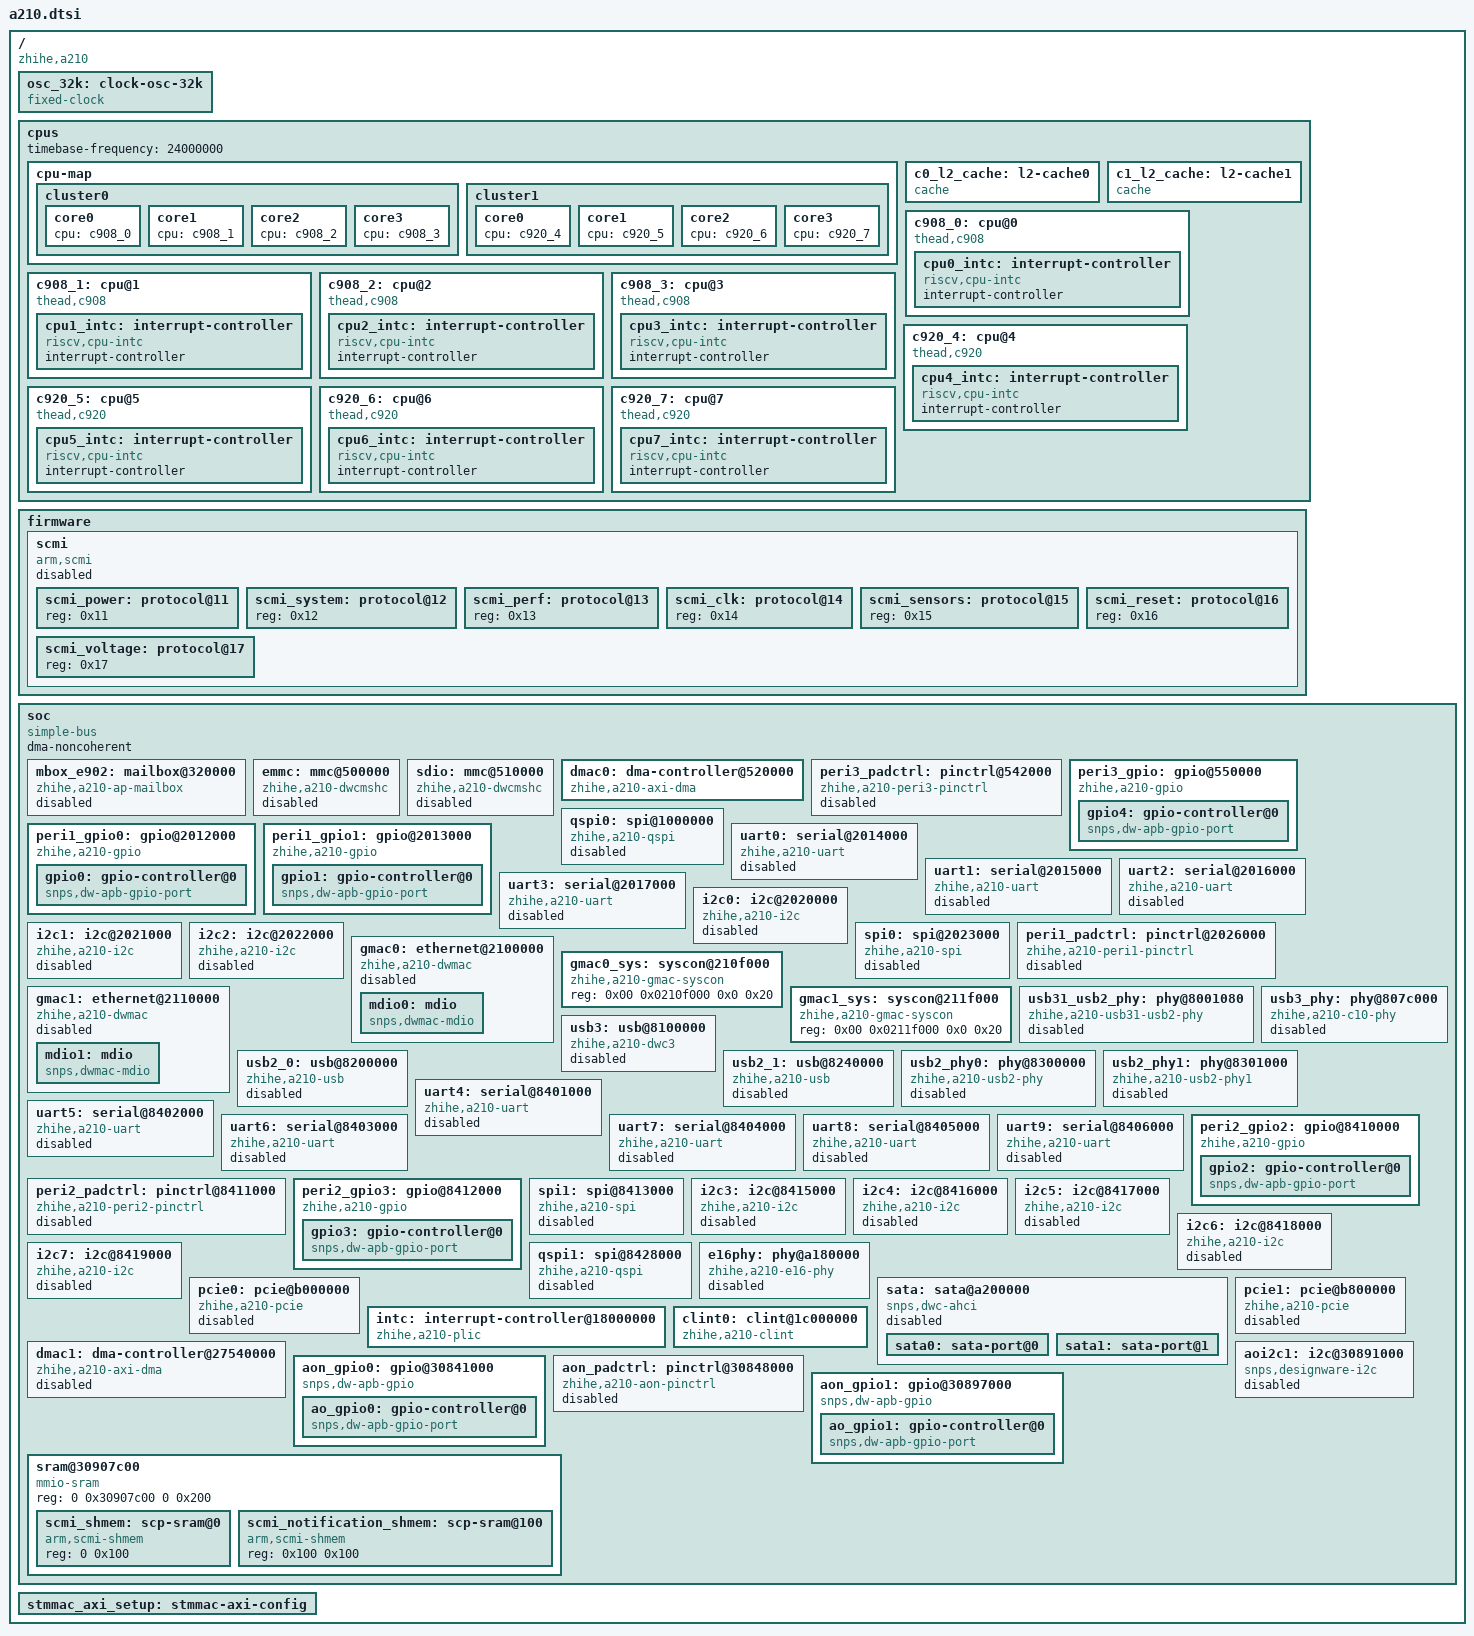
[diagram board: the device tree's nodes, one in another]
// SPDX-License-Identifier: (GPL-2.0-only OR BSD-2-Clause)
/*
 * Copyright (C) 2021 Alibaba Group Holding Limited.
 */

#include <dt-bindings/ata/ahci.h>
#include <dt-bindings/interrupt-controller/irq.h>

#include "a210-clock.h"
#include "a210-power.h"
#include "a210-reset.h"

/ {
	compatible = "zhihe,a210";
	#address-cells = <2>;
	#size-cells = <2>;

	osc_32k: clock-osc-32k {
		compatible = "fixed-clock";
		#clock-cells = <0>;
		clock-frequency = <32768>;
		clock-output-names = "osc-32k";
	};

	cpus: cpus {
		#address-cells = <1>;
		#size-cells = <0>;
		timebase-frequency = <24000000>;

		cpu-map {
			cluster0 {
				core0 {
					cpu = <&c908_0>;
				};

				core1 {
					cpu = <&c908_1>;
				};

				core2 {
					cpu = <&c908_2>;
				};

				core3 {
					cpu = <&c908_3>;
				};
			};

			cluster1 {
				core0 {
					cpu = <&c920_4>;
				};

				core1 {
					cpu = <&c920_5>;
				};

				core2 {
					cpu = <&c920_6>;
				};

				core3 {
					cpu = <&c920_7>;
				};
			};
		};

		c0_l2_cache: l2-cache0 {
			compatible = "cache";
			cache-block-size = <64>;
			cache-level = <2>;
			cache-sets = <512>;
			cache-size = <524288>;
			cache-unified;
		};

		c1_l2_cache: l2-cache1 {
			compatible = "cache";
			cache-block-size = <64>;
			cache-level = <2>;
			cache-sets = <1024>;
			cache-size = <1048576>;
			cache-unified;
		};

		c908_0: cpu@0 {
			device_type = "cpu";
			compatible = "thead,c908", "riscv";
			reg = <0>;
			d-cache-block-size = <64>;
			d-cache-sets = <256>;
			d-cache-size = <32768>;
			i-cache-block-size = <64>;
			i-cache-sets = <256>;
			i-cache-size = <32768>;
			mmu-type = "riscv,sv39";
			next-level-cache = <&c0_l2_cache>;
			riscv,cbom-block-size = <64>;
			riscv,cbop-block-size = <64>;
			riscv,cboz-block-size = <64>;
			riscv,isa-base = "rv64i";
			riscv,isa-extensions = "i", "m", "a", "f", "d", "c",
					       "b", "v", "sscofpmf", "sstc",
					       "svpbmt", "zba", "zbb", "zbc",
					       "zbs", "zicbom", "zicbop",
					       "zicboz", "zicntr", "zicsr",
					       "zifencei", "zihpm";

			cpu0_intc: interrupt-controller {
				compatible = "riscv,cpu-intc";
				#interrupt-cells = <1>;
				interrupt-controller;
			};
		};

		c908_1: cpu@1 {
			device_type = "cpu";
			compatible = "thead,c908", "riscv";
			reg = <1>;
			d-cache-block-size = <64>;
			d-cache-sets = <256>;
			d-cache-size = <32768>;
			i-cache-block-size = <64>;
			i-cache-sets = <256>;
			i-cache-size = <32768>;
			mmu-type = "riscv,sv39";
			next-level-cache = <&c0_l2_cache>;
			riscv,cbom-block-size = <64>;
			riscv,cbop-block-size = <64>;
			riscv,cboz-block-size = <64>;
			riscv,isa-base = "rv64i";
			riscv,isa-extensions = "i", "m", "a", "f", "d", "c",
					       "b", "v", "sscofpmf", "sstc",
					       "svpbmt", "zba", "zbb", "zbc",
					       "zbs", "zicbom", "zicbop",
					       "zicboz", "zicntr", "zicsr",
					       "zifencei", "zihpm";

			cpu1_intc: interrupt-controller {
				compatible = "riscv,cpu-intc";
				#interrupt-cells = <1>;
				interrupt-controller;
			};
		};

		c908_2: cpu@2 {
			device_type = "cpu";
			compatible = "thead,c908", "riscv";
			reg = <2>;
			d-cache-block-size = <64>;
			d-cache-sets = <256>;
			d-cache-size = <32768>;
			i-cache-block-size = <64>;
			i-cache-sets = <256>;
			i-cache-size = <32768>;
			mmu-type = "riscv,sv39";
			next-level-cache = <&c0_l2_cache>;
			riscv,cbom-block-size = <64>;
			riscv,cbop-block-size = <64>;
			riscv,cboz-block-size = <64>;
			riscv,isa-base = "rv64i";
			riscv,isa-extensions = "i", "m", "a", "f", "d", "c",
					       "b", "v", "sscofpmf", "sstc",
					       "svpbmt", "zba", "zbb", "zbc",
					       "zbs", "zicbom", "zicbop",
					       "zicboz", "zicntr", "zicsr",
					       "zifencei", "zihpm";

			cpu2_intc: interrupt-controller {
				compatible = "riscv,cpu-intc";
				#interrupt-cells = <1>;
				interrupt-controller;
			};
		};

		c908_3: cpu@3 {
			device_type = "cpu";
			compatible = "thead,c908", "riscv";
			reg = <3>;
			d-cache-block-size = <64>;
			d-cache-sets = <256>;
			d-cache-size = <32768>;
			i-cache-block-size = <64>;
			i-cache-sets = <256>;
			i-cache-size = <32768>;
			mmu-type = "riscv,sv39";
			next-level-cache = <&c0_l2_cache>;
			riscv,cbom-block-size = <64>;
			riscv,cbop-block-size = <64>;
			riscv,cboz-block-size = <64>;
			riscv,isa-base = "rv64i";
			riscv,isa-extensions = "i", "m", "a", "f", "d", "c",
					       "b", "v", "sscofpmf", "sstc",
					       "svpbmt", "zba", "zbb", "zbc",
					       "zbs", "zicbom", "zicbop",
					       "zicboz", "zicntr", "zicsr",
					       "zifencei", "zihpm";

			cpu3_intc: interrupt-controller {
				compatible = "riscv,cpu-intc";
				#interrupt-cells = <1>;
				interrupt-controller;
			};
		};

		c920_4: cpu@4 {
			device_type = "cpu";
			compatible = "thead,c920", "riscv";
			reg = <4>;
			d-cache-block-size = <64>;
			d-cache-sets = <512>;
			d-cache-size = <65536>;
			i-cache-block-size = <64>;
			i-cache-sets = <512>;
			i-cache-size = <65536>;
			mmu-type = "riscv,sv39";
			next-level-cache = <&c1_l2_cache>;
			riscv,cbom-block-size = <64>;
			riscv,cbop-block-size = <64>;
			riscv,cboz-block-size = <64>;
			riscv,isa-base = "rv64i";
			riscv,isa-extensions = "i", "m", "a", "f", "d", "c",
					       "b", "v", "sscofpmf", "sstc",
					       "svpbmt", "zba", "zbb", "zbc",
					       "zbs", "zicbom", "zicbop",
					       "zicboz", "zicntr", "zicsr",
					       "zifencei", "zihpm";

			cpu4_intc: interrupt-controller {
				compatible = "riscv,cpu-intc";
				#interrupt-cells = <1>;
				interrupt-controller;
			};
		};

		c920_5: cpu@5 {
			device_type = "cpu";
			compatible = "thead,c920", "riscv";
			reg = <5>;
			d-cache-block-size = <64>;
			d-cache-sets = <512>;
			d-cache-size = <65536>;
			i-cache-block-size = <64>;
			i-cache-sets = <512>;
			i-cache-size = <65536>;
			mmu-type = "riscv,sv39";
			next-level-cache = <&c1_l2_cache>;
			riscv,cbom-block-size = <64>;
			riscv,cbop-block-size = <64>;
			riscv,cboz-block-size = <64>;
			riscv,isa-base = "rv64i";
			riscv,isa-extensions = "i", "m", "a", "f", "d", "c",
					       "b", "v", "sscofpmf", "sstc",
					       "svpbmt", "zba", "zbb", "zbc",
					       "zbs", "zicbom", "zicbop",
					       "zicboz", "zicntr", "zicsr",
					       "zifencei", "zihpm";

			cpu5_intc: interrupt-controller {
				compatible = "riscv,cpu-intc";
				#interrupt-cells = <1>;
				interrupt-controller;
			};
		};

		c920_6: cpu@6 {
			device_type = "cpu";
			compatible = "thead,c920", "riscv";
			reg = <6>;
			d-cache-block-size = <64>;
			d-cache-sets = <512>;
			d-cache-size = <65536>;
			i-cache-block-size = <64>;
			i-cache-sets = <512>;
			i-cache-size = <65536>;
			mmu-type = "riscv,sv39";
			next-level-cache = <&c1_l2_cache>;
			riscv,cbom-block-size = <64>;
			riscv,cbop-block-size = <64>;
			riscv,cboz-block-size = <64>;
			riscv,isa-base = "rv64i";
			riscv,isa-extensions = "i", "m", "a", "f", "d", "c",
					       "b", "v", "sscofpmf", "sstc",
					       "svpbmt", "zba", "zbb", "zbc",
					       "zbs", "zicbom", "zicbop",
					       "zicboz", "zicntr", "zicsr",
					       "zifencei", "zihpm";

			cpu6_intc: interrupt-controller {
				compatible = "riscv,cpu-intc";
				#interrupt-cells = <1>;
				interrupt-controller;
			};
		};

		c920_7: cpu@7 {
			device_type = "cpu";
			compatible = "thead,c920", "riscv";
			reg = <7>;
			d-cache-block-size = <64>;
			d-cache-sets = <512>;
			d-cache-size = <65536>;
			i-cache-block-size = <64>;
			i-cache-sets = <512>;
			i-cache-size = <65536>;
			mmu-type = "riscv,sv39";
			next-level-cache = <&c1_l2_cache>;
			riscv,cbom-block-size = <64>;
			riscv,cbop-block-size = <64>;
			riscv,cboz-block-size = <64>;
			riscv,isa-base = "rv64i";
			riscv,isa-extensions = "i", "m", "a", "f", "d", "c",
					       "b", "v", "sscofpmf", "sstc",
					       "svpbmt", "zba", "zbb", "zbc",
					       "zbs", "zicbom", "zicbop",
					       "zicboz", "zicntr", "zicsr",
					       "zifencei", "zihpm";

			cpu7_intc: interrupt-controller {
				compatible = "riscv,cpu-intc";
				#interrupt-cells = <1>;
				interrupt-controller;
			};
		};
	};

	firmware {
		scmi: scmi {
			compatible = "arm,scmi";
			mboxes = <&mbox_e902 0>, <&mbox_e902 1>;
			mbox-names = "tx", "rx";
			shmem = <&scmi_shmem>, <&scmi_notification_shmem>;
			arm,max-rx-timeout-ms = <250>;
			#address-cells = <1>;
			#size-cells = <0>;

			status = "disabled";

			scmi_power: protocol@11 {
				reg = <0x11>;
				#power-domain-cells = <1>;
			};

			scmi_system: protocol@12 {
				reg = <0x12>;
			};

			scmi_perf: protocol@13 {
				reg = <0x13>;
				#power-domain-cells = <1>;
			};

			scmi_clk: protocol@14 {
				reg = <0x14>;
				#clock-cells = <1>;
			};

			scmi_sensors: protocol@15 {
				reg = <0x15>;
				#thermal-sensor-cells = <1>;
			};

			scmi_reset: protocol@16 {
				reg = <0x16>;
				#reset-cells = <1>;
			};

			scmi_voltage: protocol@17 {
				reg = <0x17>;
			};
		};
	};

	soc {
		compatible = "simple-bus";
		ranges;
		#address-cells = <2>;
		dma-noncoherent;
		#size-cells = <2>;

		mbox_e902: mailbox@320000 {
			compatible = "zhihe,a210-ap-mailbox";
			reg = <0 0x00320000 0 0x2000>,
			      <0 0x00311000 0 0x1000>;
			reg-names = "local", "remote";
			interrupt-parent = <&intc>;
			interrupts = <336 IRQ_TYPE_LEVEL_HIGH>;
			#mbox-cells = <1>;

			status = "disabled";
		};

		emmc: mmc@500000 {
			compatible = "zhihe,a210-dwcmshc";
			reg = <0x0 0x00500000 0x0 0x10000>;
			clocks = <&scmi_clk A210_CLK_PERI3_EMMC_SDIO_REF_CLK_CG_EN>,
				 <&scmi_clk A210_CLK_PERI3_EMMC_HCLK_EN>;
			clock-names = "core", "bus";
			interrupt-parent = <&intc>;
			interrupts = <265 IRQ_TYPE_LEVEL_HIGH>;
			power-domains = <&scmi_power A210_PD_EMMC>;

			status = "disabled";
		};

		sdio: mmc@510000 {
			compatible = "zhihe,a210-dwcmshc";
			reg = <0 0x00510000 0 0x10000>;
			clocks = <&scmi_clk A210_CLK_PERI3_EMMC_SDIO_REF_CLK_CG_EN>,
				 <&scmi_clk A210_CLK_PERI3_SDIO_HCLK_EN>;
			clock-names = "core", "bus";
			interrupt-parent = <&intc>;
			interrupts = <337 IRQ_TYPE_LEVEL_HIGH>;
			power-domains = <&scmi_power A210_PD_SDIO>;

			status = "disabled";
		};

		dmac0: dma-controller@520000 {
			compatible = "zhihe,a210-axi-dma", "snps,axi-dma-1.01a";
			reg = <0x00 0x00520000 0x0 0x4000>;
			clocks = <&scmi_clk A210_CLK_PERI3_DMAC_ACLK_EN>,
				 <&scmi_clk A210_CLK_PERI3_DMAC_HCLK_EN>;
			clock-names = "core-clk", "cfgr-clk";
			#dma-cells = <1>;
			dma-channels = <16>;
			interrupt-parent = <&intc>;
			interrupts = <264 IRQ_TYPE_LEVEL_HIGH>;
			power-domains = <&scmi_power A210_PD_DMAC>;
			resets = <&scmi_reset A210_RESET_PERI3_DMAC_ARST>,
				 <&scmi_reset A210_RESET_PERI3_DMAC_HRST>;
			snps,axi-max-burst-len = <4>;
			snps,block-size = <65536 65536 65536 65536
					  65536 65536 65536 65536
					  65536 65536 65536 65536
					  65536 65536 65536 65536>;
			snps,data-width = <4>;
			snps,dma-masters = <1>;
			snps,priority = <0 0 0 0 0 0 0 0 0 0 0 0 0 0 0 0>;
		};

		peri3_padctrl: pinctrl@542000 {
			compatible = "zhihe,a210-peri3-pinctrl";
			reg = <0x0 0x00542000 0x0 0x1000>;
			clocks = <&scmi_clk A210_CLK_PERI3_PAD>;
			clock-names = "pclk";
			resets = <&scmi_reset A210_RESET_PERI3_PAD>;

			status = "disabled";
		};

		peri3_gpio: gpio@550000 {
			compatible = "zhihe,a210-gpio", "snps,dw-apb-gpio";
			reg = <0x00 0x00550000 0x0 0x10000>;
			#address-cells = <1>;
			clocks = <&scmi_clk A210_CLK_PERI3_GPIO4_PCLK_EN>,
				 <&scmi_clk A210_CLK_PERI3_GPIO4_DBCLK_EN>;
			clock-names = "bus", "db";
			resets = <&scmi_reset A210_RESET_PERI3_GPIO4_PRST>,
				 <&scmi_reset A210_RESET_PERI3_GPIO4_DBRST>;
			#size-cells = <0>;

			gpio4: gpio-controller@0 {
				compatible = "snps,dw-apb-gpio-port";
				reg = <0>;
				#gpio-cells = <2>;
				gpio-controller;
				gpio-ranges = <&peri3_padctrl 0 0 6>;
				#interrupt-cells = <2>;
				interrupt-controller;
				interrupt-parent = <&intc>;
				interrupts = <52 IRQ_TYPE_LEVEL_HIGH>;
				ngpios = <6>;
			};
		};

		qspi0: spi@1000000 {
			compatible = "zhihe,a210-qspi", "snps,dwc-ssi-1.01a";
			reg = <0x00 0x01000000 0x0 0x4000>;
			#address-cells = <1>;
			clocks = <&scmi_clk A210_CLK_PERI1_QSPI0_SSI_CLK_EN>,
				 <&scmi_clk A210_CLK_PERI1_QSPI0_PCLK_EN>;
			clock-names = "ssi_clk", "pclk";
			interrupt-parent = <&intc>;
			interrupts = <308 IRQ_TYPE_LEVEL_HIGH>;
			num-cs = <2>;
			power-domains = <&scmi_power A210_PD_TOP>;
			resets = <&scmi_reset A210_RESET_PERI1_QSPI0_SSI_RST>,
				 <&scmi_reset A210_RESET_PERI1_QSPI0_PRST>;
			#size-cells = <0>;

			status = "disabled";
		};

		peri1_gpio0: gpio@2012000 {
			compatible = "zhihe,a210-gpio", "snps,dw-apb-gpio";
			reg = <0x00 0x02012000 0x0 0x1000>;
			#address-cells = <1>;
			clocks = <&scmi_clk A210_CLK_PERI1_GPIO0_PCLK_EN>,
				 <&scmi_clk A210_CLK_PERI1_GPIO0_DBCLK_EN>;
			clock-names = "bus", "db";
			resets = <&scmi_reset A210_RESET_PERI1_GPIO0_PRST>,
				 <&scmi_reset A210_RESET_PERI1_GPIO0_DBRST>;
			#size-cells = <0>;

			gpio0: gpio-controller@0 {
				compatible = "snps,dw-apb-gpio-port";
				reg = <0>;
				#gpio-cells = <2>;
				gpio-controller;
				gpio-ranges = <&peri1_padctrl 0 0 32>;
				#interrupt-cells = <2>;
				interrupt-controller;
				interrupt-parent = <&intc>;
				interrupts = <289 IRQ_TYPE_LEVEL_HIGH>;
				ngpios = <32>;
			};
		};

		peri1_gpio1: gpio@2013000 {
			compatible = "zhihe,a210-gpio", "snps,dw-apb-gpio";
			reg = <0x00 0x02013000 0x0 0x1000>;
			#address-cells = <1>;
			clocks = <&scmi_clk A210_CLK_PERI1_GPIO1_PCLK_EN>,
				 <&scmi_clk A210_CLK_PERI1_GPIO1_DBCLK_EN>;
			clock-names = "bus", "db";
			resets = <&scmi_reset A210_RESET_PERI1_GPIO1_PRST>,
				 <&scmi_reset A210_RESET_PERI1_GPIO1_DBRST>;
			#size-cells = <0>;

			gpio1: gpio-controller@0 {
				compatible = "snps,dw-apb-gpio-port";
				reg = <0>;
				#gpio-cells = <2>;
				gpio-controller;
				gpio-ranges = <&peri1_padctrl 0 32 18>;
				#interrupt-cells = <2>;
				interrupt-controller;
				interrupt-parent = <&intc>;
				interrupts = <290 IRQ_TYPE_LEVEL_HIGH>;
				ngpios = <18>;
			};
		};

		uart0: serial@2014000 {
			compatible = "zhihe,a210-uart", "snps,dw-apb-uart";
			reg = <0x0 0x02014000 0x0 0x1000>;
			clocks = <&scmi_clk A210_CLK_UART_SCLK(0)>,
				 <&scmi_clk A210_CLK_UART_PCLK(0)>;
			clock-names = "baudclk", "apb_pclk";
			interrupt-parent = <&intc>;
			interrupts = <321 IRQ_TYPE_LEVEL_HIGH>;
			reg-io-width = <4>;
			reg-shift = <2>;
			resets = <&scmi_reset A210_RESET_UART_PRST(0)>,
				 <&scmi_reset A210_RESET_UART_SRST(0)>;

			status = "disabled";
		};

		uart1: serial@2015000 {
			compatible = "zhihe,a210-uart", "snps,dw-apb-uart";
			reg = <0x0 0x02015000 0x0 0x1000>;
			clocks = <&scmi_clk A210_CLK_UART_SCLK(1)>,
				 <&scmi_clk A210_CLK_UART_PCLK(1)>;
			clock-names = "baudclk", "apb_pclk";
			interrupt-parent = <&intc>;
			interrupts = <322 IRQ_TYPE_LEVEL_HIGH>;
			reg-io-width = <4>;
			reg-shift = <2>;
			resets = <&scmi_reset A210_RESET_UART_PRST(1)>,
				 <&scmi_reset A210_RESET_UART_SRST(1)>;

			status = "disabled";
		};

		uart2: serial@2016000 {
			compatible = "zhihe,a210-uart", "snps,dw-apb-uart";
			reg = <0x0 0x02016000 0x0 0x1000>;
			clocks = <&scmi_clk A210_CLK_UART_SCLK(2)>,
				 <&scmi_clk A210_CLK_UART_PCLK(2)>;
			clock-names = "baudclk", "apb_pclk";
			interrupt-parent = <&intc>;
			interrupts = <323 IRQ_TYPE_LEVEL_HIGH>;
			reg-io-width = <4>;
			reg-shift = <2>;
			resets = <&scmi_reset A210_RESET_UART_PRST(2)>,
				 <&scmi_reset A210_RESET_UART_SRST(2)>;

			status = "disabled";
		};

		uart3: serial@2017000 {
			compatible = "zhihe,a210-uart", "snps,dw-apb-uart";
			reg = <0x0 0x02017000 0x0 0x1000>;
			clocks = <&scmi_clk A210_CLK_UART_SCLK(3)>,
				 <&scmi_clk A210_CLK_UART_PCLK(3)>;
			clock-names = "baudclk", "apb_pclk";
			interrupt-parent = <&intc>;
			interrupts = <324 IRQ_TYPE_LEVEL_HIGH>;
			reg-io-width = <4>;
			reg-shift = <2>;
			resets = <&scmi_reset A210_RESET_UART_PRST(3)>,
				 <&scmi_reset A210_RESET_UART_SRST(3)>;

			status = "disabled";
		};

		i2c0: i2c@2020000 {
			compatible = "zhihe,a210-i2c", "snps,designware-i2c";
			reg = <0x00 0x02020000 0x0 0x1000>;
			#address-cells = <1>;
			clocks = <&scmi_clk A210_CLK_PERI1_I2C0_IC_CLK_EN>,
				 <&scmi_clk A210_CLK_PERI1_I2C0_PCLK_EN>;
			clock-names = "ref", "pclk";
			dmas = <&dmac0 21>, <&dmac0 20>;
			dma-names = "tx", "rx";
			interrupt-parent = <&intc>;
			interrupts = <293 IRQ_TYPE_LEVEL_HIGH>;
			resets = <&scmi_reset A210_RESET_PERI1_I2C0_IC_RST>,
				 <&scmi_reset A210_RESET_PERI1_I2C0_PRST>;
			#size-cells = <0>;

			status = "disabled";
		};

		i2c1: i2c@2021000 {
			compatible = "zhihe,a210-i2c", "snps,designware-i2c";
			reg = <0x00 0x02021000 0x0 0x1000>;
			#address-cells = <1>;
			clocks = <&scmi_clk A210_CLK_PERI1_I2C1_IC_CLK_EN>,
				 <&scmi_clk A210_CLK_PERI1_I2C1_PCLK_EN>;
			clock-names = "ref", "pclk";
			interrupt-parent = <&intc>;
			interrupts = <294 IRQ_TYPE_LEVEL_HIGH>;
			resets = <&scmi_reset A210_RESET_PERI1_I2C1_IC_RST>,
				 <&scmi_reset A210_RESET_PERI1_I2C1_PRST>;
			#size-cells = <0>;

			status = "disabled";
		};

		i2c2: i2c@2022000 {
			compatible = "zhihe,a210-i2c", "snps,designware-i2c";
			reg = <0x00 0x02022000 0x0 0x1000>;
			#address-cells = <1>;
			clocks = <&scmi_clk A210_CLK_PERI1_I2C2_IC_CLK_EN>,
				 <&scmi_clk A210_CLK_PERI1_I2C2_PCLK_EN>;
			clock-names = "ref", "pclk";
			interrupt-parent = <&intc>;
			interrupts = <295 IRQ_TYPE_LEVEL_HIGH>;
			resets = <&scmi_reset A210_RESET_PERI1_I2C2_IC_RST>,
				 <&scmi_reset A210_RESET_PERI1_I2C2_PRST>;
			#size-cells = <0>;

			status = "disabled";
		};

		spi0: spi@2023000 {
			compatible = "zhihe,a210-spi", "snps,dw-apb-ssi";
			reg = <0x00 0x02023000 0x0 0x1000>;
			#address-cells = <1>;
			clocks = <&scmi_clk A210_CLK_PERI1_SPI0_SSI_CLK_EN>,
				 <&scmi_clk A210_CLK_PERI1_SPI0_PCLK_EN>;
			clock-names = "ssi_clk", "pclk";
			dmas = <&dmac0 9>, <&dmac0 8>;
			dma-names = "tx", "rx";
			interrupt-parent = <&intc>;
			interrupts = <310 IRQ_TYPE_LEVEL_HIGH>;
			num-cs = <2>;
			power-domains = <&scmi_power A210_PD_TOP>;
			resets = <&scmi_reset A210_RESET_PERI1_SPI0_SSI_RST>,
				 <&scmi_reset A210_RESET_PERI1_SPI0_PRST>;
			#size-cells = <0>;

			status = "disabled";
		};

		peri1_padctrl: pinctrl@2026000 {
			compatible = "zhihe,a210-peri1-pinctrl";
			reg = <0x0 0x02026000 0x0 0x1000>;
			clocks = <&scmi_clk A210_CLK_PERI1_PAD>;
			clock-names = "pclk";
			resets = <&scmi_reset A210_RESET_PERI1_PAD>;

			status = "disabled";
		};

		gmac0: ethernet@2100000 {
			compatible = "zhihe,a210-dwmac", "snps,dwmac-5.40a";
			reg = <0x00 0x02100000 0x0 0x10000>;
			reg-names = "gmac";
			clocks = <&scmi_clk A210_CLK_PERI1_GMAC0_ACLK_EN>,
				 <&scmi_clk A210_CLK_PERI1_GMAC0_HCLK_EN>;
			clock-names = "stmmaceth", "pclk";
			interrupt-parent = <&intc>;
			interrupts = <277 IRQ_TYPE_LEVEL_HIGH>;
			interrupt-names = "macirq";
			power-domains = <&scmi_power A210_PD_GMAC0>;
			resets = <&scmi_reset A210_RESET_PERI1_GMAC0_ARST>,
				 <&scmi_reset A210_RESET_PERI1_GMAC0_HRST>;
			reset-names = "stmmaceth", "ahb";
			snps,axi-config = <&stmmac_axi_setup>;
			snps,fixed-burst;
			snps,pbl = <32>;
			snps,tso;
			zhihe,gmacsys = <&gmac0_sys>;

			status = "disabled";

			mdio0: mdio {
				compatible = "snps,dwmac-mdio";
				#address-cells = <1>;
				#size-cells = <0>;
			};
		};

		gmac0_sys: syscon@210f000 {
			compatible = "zhihe,a210-gmac-syscon", "syscon";
			reg = <0x00 0x0210f000 0x0 0x20>;
		};

		gmac1: ethernet@2110000 {
			compatible = "zhihe,a210-dwmac", "snps,dwmac-5.40a";
			reg = <0x00 0x02110000 0x0 0x10000>;
			reg-names = "gmac";
			clocks = <&scmi_clk A210_CLK_PERI1_GMAC1_ACLK_EN>,
				 <&scmi_clk A210_CLK_PERI1_GMAC1_HCLK_EN>;
			clock-names = "stmmaceth", "pclk";
			interrupt-parent = <&intc>;
			interrupts = <288 IRQ_TYPE_LEVEL_HIGH>;
			interrupt-names = "macirq";
			power-domains = <&scmi_power A210_PD_GMAC1>;
			resets = <&scmi_reset A210_RESET_PERI1_GMAC1_ARST>,
				 <&scmi_reset A210_RESET_PERI1_GMAC1_HRST>;
			reset-names = "stmmaceth", "ahb";
			snps,axi-config = <&stmmac_axi_setup>;
			snps,fixed-burst;
			snps,pbl = <32>;
			snps,tso;
			zhihe,gmacsys = <&gmac1_sys>;

			status = "disabled";

			mdio1: mdio {
				compatible = "snps,dwmac-mdio";
				#address-cells = <1>;
				#size-cells = <0>;
			};
		};

		gmac1_sys: syscon@211f000 {
			compatible = "zhihe,a210-gmac-syscon", "syscon";
			reg = <0x00 0x0211f000 0x0 0x20>;
		};

		usb31_usb2_phy: phy@8001080 {
			compatible = "zhihe,a210-usb31-usb2-phy";
			reg = <0 0x08001080 0 0x28>;
			clocks = <&scmi_clk A210_CLK_USB31_PCLK_EN>;
			clock-names = "apb";
			#phy-cells = <0>;
			power-domains = <&scmi_power A210_PD_USB>;
			resets = <&scmi_reset A210_RESET_USB_USB31_PHY_RST>;
			reset-names = "phy";

			status = "disabled";
		};

		usb3_phy: phy@807c000 {
			compatible = "zhihe,a210-c10-phy";
			reg = <0 0x0807c000 0 0x100>;
			clocks = <&scmi_clk A210_CLK_C10PHY_PCLK_EN>,
				 <&scmi_clk A210_CLK_USB31_REF_CLK_EN>,
				 <&scmi_clk A210_CLK_C10PHY_SUSPEND_CLK_EN>;
			clock-names = "apb", "ref", "suspend";
			#phy-cells = <0>;
			power-domains = <&scmi_power A210_PD_USB>;
			resets = <&scmi_reset A210_RESET_USB_C10PHY_APBS_PRST>,
				 <&scmi_reset A210_RESET_USB_C10PHY_PHY_RST>;
			reset-names = "apb", "phy";

			status = "disabled";
		};

		usb3: usb@8100000 {
			compatible = "zhihe,a210-dwc3", "snps,dwc3";
			reg = <0 0x08100000 0 0x100000>;
			clocks = <&scmi_clk A210_CLK_USB31_BUS_CLK_EN>,
				 <&scmi_clk A210_CLK_USB31_REF_CLK_EN>,
				 <&scmi_clk A210_CLK_USB31_SUSPEND_CLK_EN>;
			clock-names = "bus_early", "ref", "suspend";
			interrupt-parent = <&intc>;
			interrupts = <183 IRQ_TYPE_LEVEL_HIGH>;
			phys = <&usb31_usb2_phy>, <&usb3_phy>;
			phy-names = "usb2-phy", "usb3-phy";
			power-domains = <&scmi_power A210_PD_USB>;
			resets = <&scmi_reset A210_RESET_USB_USB31_VCC_RST>;

			status = "disabled";
		};

		usb2_0: usb@8200000 {
			compatible = "zhihe,a210-usb", "snps,dwc2";
			reg = <0 0x08200000 0 0x40000>;
			clocks = <&scmi_clk A210_CLK_USB20_WRAP0_HCLK>;
			clock-names = "otg";
			g-np-tx-fifo-size = <16>;
			g-rx-fifo-size = <275>;
			g-tx-fifo-size = <256 128 128 64 64 32>;
			interrupt-parent = <&intc>;
			interrupts = <181 IRQ_TYPE_LEVEL_HIGH>;
			maximum-speed = "high-speed";
			phys = <&usb2_phy0>;
			phy-names = "usb2-phy";
			power-domains = <&scmi_power A210_PD_USB>;
			resets = <&scmi_reset A210_RESET_USB_USB20_BLK_USB2_WRAP0_HRST>;
			reset-names = "dwc2";

			status = "disabled";
		};

		usb2_1: usb@8240000 {
			compatible = "zhihe,a210-usb", "snps,dwc2";
			reg = <0 0x08240000 0 0x40000>;
			clocks = <&scmi_clk A210_CLK_USB20_WRAP1_HCLK>;
			clock-names = "otg";
			g-np-tx-fifo-size = <16>;
			g-rx-fifo-size = <275>;
			g-tx-fifo-size = <256 128 128 64 64 32>;
			interrupt-parent = <&intc>;
			interrupts = <182 IRQ_TYPE_LEVEL_HIGH>;
			maximum-speed = "high-speed";
			phys = <&usb2_phy1>;
			phy-names = "usb2-phy";
			power-domains = <&scmi_power A210_PD_USB>;
			resets = <&scmi_reset A210_RESET_USB_USB20_BLK_USB2_WRAP1_HRST>;
			reset-names = "dwc2";

			status = "disabled";
		};

		usb2_phy0: phy@8300000 {
			compatible = "zhihe,a210-usb2-phy";
			reg = <0 0x08300000 0 0x20>;
			clocks = <&scmi_clk A210_CLK_USB20_SYSREG_PCLK>;
			clock-names = "apb";
			#phy-cells = <0>;
			power-domains = <&scmi_power A210_PD_USB>;
			resets = <&scmi_reset A210_RESET_USB_USB20_BLK_USB0_PHY_PON_RESET>;
			reset-names = "phy";

			status = "disabled";
		};

		usb2_phy1: phy@8301000 {
			compatible = "zhihe,a210-usb2-phy1";
			reg = <0 0x08301000 0 0x20>;
			clocks = <&scmi_clk A210_CLK_USB20_SYSREG_PCLK>;
			clock-names = "apb";
			#phy-cells = <0>;
			power-domains = <&scmi_power A210_PD_USB>;
			resets = <&scmi_reset A210_RESET_USB_USB20_BLK_USB1_PHY_PON_RESET>;
			reset-names = "phy";

			status = "disabled";
		};

		uart4: serial@8401000 {
			compatible = "zhihe,a210-uart", "snps,dw-apb-uart";
			reg = <0x0 0x08401000 0x0 0x1000>;
			clocks = <&scmi_clk A210_CLK_UART_SCLK(4)>,
				 <&scmi_clk A210_CLK_UART_PCLK(4)>;
			clock-names = "baudclk", "apb_pclk";
			interrupt-parent = <&intc>;
			interrupts = <325 IRQ_TYPE_LEVEL_HIGH>;
			reg-io-width = <4>;
			reg-shift = <2>;
			resets = <&scmi_reset A210_RESET_UART_PRST(4)>,
				 <&scmi_reset A210_RESET_UART_SRST(4)>;

			status = "disabled";
		};

		uart5: serial@8402000 {
			compatible = "zhihe,a210-uart", "snps,dw-apb-uart";
			reg = <0x0 0x08402000 0x0 0x1000>;
			clocks = <&scmi_clk A210_CLK_UART_SCLK(5)>,
				 <&scmi_clk A210_CLK_UART_PCLK(5)>;
			clock-names = "baudclk", "apb_pclk";
			interrupt-parent = <&intc>;
			interrupts = <326 IRQ_TYPE_LEVEL_HIGH>;
			reg-io-width = <4>;
			reg-shift = <2>;
			resets = <&scmi_reset A210_RESET_UART_PRST(5)>,
				 <&scmi_reset A210_RESET_UART_SRST(5)>;

			status = "disabled";
		};

		uart6: serial@8403000 {
			compatible = "zhihe,a210-uart", "snps,dw-apb-uart";
			reg = <0x0 0x08403000 0x0 0x1000>;
			clocks = <&scmi_clk A210_CLK_UART_SCLK(6)>,
				 <&scmi_clk A210_CLK_UART_PCLK(6)>;
			clock-names = "baudclk", "apb_pclk";
			interrupt-parent = <&intc>;
			interrupts = <327 IRQ_TYPE_LEVEL_HIGH>;
			reg-io-width = <4>;
			reg-shift = <2>;
			resets = <&scmi_reset A210_RESET_UART_PRST(6)>,
				 <&scmi_reset A210_RESET_UART_SRST(6)>;

			status = "disabled";
		};

		uart7: serial@8404000 {
			compatible = "zhihe,a210-uart", "snps,dw-apb-uart";
			reg = <0x0 0x08404000 0x0 0x1000>;
			clocks = <&scmi_clk A210_CLK_UART_SCLK(7)>,
				 <&scmi_clk A210_CLK_UART_PCLK(7)>;
			clock-names = "baudclk", "apb_pclk";
			interrupt-parent = <&intc>;
			interrupts = <328 IRQ_TYPE_LEVEL_HIGH>;
			reg-io-width = <4>;
			reg-shift = <2>;
			resets = <&scmi_reset A210_RESET_UART_PRST(7)>,
				 <&scmi_reset A210_RESET_UART_SRST(7)>;

			status = "disabled";
		};

		uart8: serial@8405000 {
			compatible = "zhihe,a210-uart", "snps,dw-apb-uart";
			reg = <0x0 0x08405000 0x0 0x1000>;
			clocks = <&scmi_clk A210_CLK_UART_SCLK(8)>,
				 <&scmi_clk A210_CLK_UART_PCLK(8)>;
			clock-names = "baudclk", "apb_pclk";
			interrupt-parent = <&intc>;
			interrupts = <329 IRQ_TYPE_LEVEL_HIGH>;
			reg-io-width = <4>;
			reg-shift = <2>;
			resets = <&scmi_reset A210_RESET_UART_PRST(8)>,
				 <&scmi_reset A210_RESET_UART_SRST(8)>;

			status = "disabled";
		};

		uart9: serial@8406000 {
			compatible = "zhihe,a210-uart", "snps,dw-apb-uart";
			reg = <0x0 0x08406000 0x0 0x1000>;
			clocks = <&scmi_clk A210_CLK_UART_SCLK(9)>,
				 <&scmi_clk A210_CLK_UART_PCLK(9)>;
			clock-names = "baudclk", "apb_pclk";
			interrupt-parent = <&intc>;
			interrupts = <330 IRQ_TYPE_LEVEL_HIGH>;
			reg-io-width = <4>;
			reg-shift = <2>;
			resets = <&scmi_reset A210_RESET_UART_PRST(9)>,
				 <&scmi_reset A210_RESET_UART_SRST(9)>;

			status = "disabled";
		};

		peri2_gpio2: gpio@8410000 {
			compatible = "zhihe,a210-gpio", "snps,dw-apb-gpio";
			reg = <0x00 0x08410000 0x0 0x1000>;
			#address-cells = <1>;
			clocks = <&scmi_clk A210_CLK_PERI2_GPIO2_PCLK_EN>,
				 <&scmi_clk A210_CLK_PERI2_GPIO2_DBCLK_EN>;
			clock-names = "bus", "db";
			resets = <&scmi_reset A210_RESET_PERI2_GPIO2_PRST>,
				 <&scmi_reset A210_RESET_PERI2_GPIO2_DBRST>;
			#size-cells = <0>;

			gpio2: gpio-controller@0 {
				compatible = "snps,dw-apb-gpio-port";
				reg = <0>;
				#gpio-cells = <2>;
				gpio-controller;
				gpio-ranges = <&peri2_padctrl 0 0 32>;
				#interrupt-cells = <2>;
				interrupt-controller;
				interrupt-parent = <&intc>;
				interrupts = <291 IRQ_TYPE_LEVEL_HIGH>;
				ngpios = <32>;
			};
		};

		peri2_padctrl: pinctrl@8411000 {
			compatible = "zhihe,a210-peri2-pinctrl";
			reg = <0x0 0x08411000 0x0 0x1000>;
			clocks = <&scmi_clk A210_CLK_PERI2_PAD>;
			clock-names = "pclk";
			resets = <&scmi_reset A210_RESET_PERI2_PAD>;

			status = "disabled";
		};

		peri2_gpio3: gpio@8412000 {
			compatible = "zhihe,a210-gpio", "snps,dw-apb-gpio";
			reg = <0x00 0x08412000 0x0 0x1000>;
			#address-cells = <1>;
			clocks = <&scmi_clk A210_CLK_PERI2_GPIO3_PCLK_EN>,
				 <&scmi_clk A210_CLK_PERI2_GPIO3_DBCLK_EN>;
			clock-names = "bus", "db";
			resets = <&scmi_reset A210_RESET_PERI2_GPIO3_PRST>,
				 <&scmi_reset A210_RESET_PERI2_GPIO3_DBRST>;
			#size-cells = <0>;

			gpio3: gpio-controller@0 {
				compatible = "snps,dw-apb-gpio-port";
				reg = <0>;
				#gpio-cells = <2>;
				gpio-controller;
				gpio-ranges = <&peri2_padctrl 0 32 11>;
				#interrupt-cells = <2>;
				interrupt-controller;
				interrupt-parent = <&intc>;
				interrupts = <292 IRQ_TYPE_LEVEL_HIGH>;
				ngpios = <11>;
			};
		};

		spi1: spi@8413000 {
			compatible = "zhihe,a210-spi", "snps,dw-apb-ssi";
			reg = <0x00 0x08413000 0x0 0x1000>;
			#address-cells = <1>;
			clocks = <&scmi_clk A210_CLK_PERI2_SPI1_SSI_CLK_EN>,
				 <&scmi_clk A210_CLK_PERI2_SPI1_PCLK_EN>;
			clock-names = "ssi_clk", "pclk";
			dmas = <&dmac0 62>, <&dmac0 61>;
			dma-names = "tx", "rx";
			interrupt-parent = <&intc>;
			interrupts = <311 IRQ_TYPE_LEVEL_HIGH>;
			num-cs = <2>;
			power-domains = <&scmi_power A210_PD_TOP>;
			resets = <&scmi_reset A210_RESET_PERI2_SPI1_SSI_RST>,
				 <&scmi_reset A210_RESET_PERI2_SPI1_PRST>;
			#size-cells = <0>;

			status = "disabled";
		};

		i2c3: i2c@8415000 {
			compatible = "zhihe,a210-i2c", "snps,designware-i2c";
			reg = <0x00 0x08415000 0x0 0x1000>;
			#address-cells = <1>;
			clocks = <&scmi_clk A210_CLK_PERI2_I2C3_IC_CLK_EN>,
				 <&scmi_clk A210_CLK_PERI2_I2C3_PCLK_EN>;
			clock-names = "ref", "pclk";
			interrupt-parent = <&intc>;
			interrupts = <296 IRQ_TYPE_LEVEL_HIGH>;
			resets = <&scmi_reset A210_RESET_PERI2_I2C3_IC_RST>,
				 <&scmi_reset A210_RESET_PERI2_I2C3_PRST>;
			#size-cells = <0>;

			status = "disabled";
		};

		i2c4: i2c@8416000 {
			compatible = "zhihe,a210-i2c", "snps,designware-i2c";
			reg = <0x00 0x08416000 0x0 0x1000>;
			#address-cells = <1>;
			clocks = <&scmi_clk A210_CLK_PERI2_I2C4_IC_CLK_EN>,
				 <&scmi_clk A210_CLK_PERI2_I2C4_PCLK_EN>;
			clock-names = "ref", "pclk";
			interrupt-parent = <&intc>;
			interrupts = <297 IRQ_TYPE_LEVEL_HIGH>;
			resets = <&scmi_reset A210_RESET_PERI2_I2C4_IC_RST>,
				 <&scmi_reset A210_RESET_PERI2_I2C4_PRST>;
			#size-cells = <0>;

			status = "disabled";
		};

		i2c5: i2c@8417000 {
			compatible = "zhihe,a210-i2c", "snps,designware-i2c";
			reg = <0x00 0x08417000 0x0 0x1000>;
			#address-cells = <1>;
			clocks = <&scmi_clk A210_CLK_PERI2_I2C5_IC_CLK_EN>,
				 <&scmi_clk A210_CLK_PERI2_I2C5_PCLK_EN>;
			clock-names = "ref", "pclk";
			interrupt-parent = <&intc>;
			interrupts = <298 IRQ_TYPE_LEVEL_HIGH>;
			resets = <&scmi_reset A210_RESET_PERI2_I2C5_IC_RST>,
				 <&scmi_reset A210_RESET_PERI2_I2C5_PRST>;
			#size-cells = <0>;

			status = "disabled";
		};

		i2c6: i2c@8418000 {
			compatible = "zhihe,a210-i2c", "snps,designware-i2c";
			reg = <0x00 0x08418000 0x0 0x1000>;
			#address-cells = <1>;
			clocks = <&scmi_clk A210_CLK_PERI2_I2C6_IC_CLK_EN>,
				 <&scmi_clk A210_CLK_PERI2_I2C6_PCLK_EN>;
			clock-names = "ref", "pclk";
			interrupt-parent = <&intc>;
			interrupts = <299 IRQ_TYPE_LEVEL_HIGH>;
			resets = <&scmi_reset A210_RESET_PERI2_I2C6_IC_RST>,
				 <&scmi_reset A210_RESET_PERI2_I2C6_PRST>;
			#size-cells = <0>;

			status = "disabled";
		};

		i2c7: i2c@8419000 {
			compatible = "zhihe,a210-i2c", "snps,designware-i2c";
			reg = <0x00 0x08419000 0x0 0x1000>;
			#address-cells = <1>;
			clocks = <&scmi_clk A210_CLK_PERI2_I2C7_IC_CLK_EN>,
				 <&scmi_clk A210_CLK_PERI2_I2C7_PCLK_EN>;
			clock-names = "ref", "pclk";
			interrupt-parent = <&intc>;
			interrupts = <300 IRQ_TYPE_LEVEL_HIGH>;
			resets = <&scmi_reset A210_RESET_PERI2_I2C7_IC_RST>,
				 <&scmi_reset A210_RESET_PERI2_I2C7_PRST>;
			#size-cells = <0>;

			status = "disabled";
		};

		qspi1: spi@8428000 {
			compatible = "zhihe,a210-qspi", "snps,dwc-ssi-1.01a";
			reg = <0x00 0x08428000 0x0 0x4000>;
			#address-cells = <1>;
			clocks = <&scmi_clk A210_CLK_PERI2_QSPI1_SSI_CLK_EN>,
				 <&scmi_clk A210_CLK_PERI2_QSPI1_PCLK_EN>;
			clock-names = "ssi_clk", "pclk";
			interrupt-parent = <&intc>;
			interrupts = <309 IRQ_TYPE_LEVEL_HIGH>;
			num-cs = <2>;
			power-domains = <&scmi_power A210_PD_TOP>;
			resets = <&scmi_reset A210_RESET_PERI2_QSPI1_SSI_RST>,
				 <&scmi_reset A210_RESET_PERI2_QSPI1_PRST>;
			#size-cells = <0>;

			status = "disabled";
		};

		e16phy: phy@a180000 {
			compatible = "zhihe,a210-e16-phy";
			reg = <0 0x0a180000 0 0x1000>,
			      <0 0x0a100000 0 0x40000>,
			      <0 0x0a140000 0 0x40000>;
			reg-names = "sysreg", "phy0", "phy1";
			#phy-cells = <0>;
			resets = <&scmi_reset A210_RESET_PCIE_E16PHY_APBS_PRST>,
				 <&scmi_reset A210_RESET_PCIE_E16PHY_PHY_RST>;
			reset-names = "apb", "phy";

			status = "disabled";
		};

		sata: sata@a200000 {
			compatible = "snps,dwc-ahci";
			reg = <0 0x0a200000 0 0x100000>;
			#address-cells = <1>;
			clocks = <&scmi_clk A210_CLK_SATA_GEN3X2_ACLK_EN>,
				 <&scmi_clk A210_CLK_SATA_PMALIVE_CLK_EN>;
			clock-names = "aclk", "pmalive";
			interrupt-parent = <&intc>;
			interrupts = <170 IRQ_TYPE_LEVEL_HIGH>;
			power-domains = <&scmi_power A210_PD_SATA>;
			resets = <&scmi_reset A210_RESET_PCIE_SATA_ARESET>,
				 <&scmi_reset A210_RESET_PCIE_SATA_RST_PMALIVE>;
			reset-names = "arst", "pmalive";
			#size-cells = <0>;

			status = "disabled";

			sata0: sata-port@0 {
				reg = <0>;
				phys = <&e16phy>;
				phy-names = "sata-phy";
			};

			sata1: sata-port@1 {
				reg = <1>;
				phys = <&e16phy>;
				phy-names = "sata-phy";
			};
		};

		pcie0: pcie@b000000 {
			device_type = "pci";
			compatible = "zhihe,a210-pcie";
			reg = <0 0x0b000000 0 0x800000>,
			      <0x18 0 0 0x200000>, <0 0x0a004000 0 0x1000>;
			reg-names = "dbi", "config", "app";
			ranges = <0x01000000 0 0 0x18 0x200000 0 0x10000>,
				 <0x02000000 0 0x40100000 0 0x40100000 0 0x800000>,
				 <0x43000000 0x18 0x300000 0x18 0x300000
				 0 0x800000>;
			#address-cells = <3>;
			bus-range = <0 255>;
			clocks = <&scmi_clk A210_CLK_PCIE_DM_GEN3X4_AUX_CLK_EN>,
				 <&scmi_clk A210_CLK_PCIE_DM_GEN3X4_SLV_ACLK_EN>,
				 <&scmi_clk A210_CLK_PCIE_DM_GEN3X4_MST_ACLK_EN>,
				 <&scmi_clk A210_CLK_PCIE_DM_GEN3X4_PCLK_EN>;
			clock-names = "aux", "slv", "mstr", "dbi";
			#interrupt-cells = <1>;
			interrupt-map = <0 0 0 1 &intc 140 IRQ_TYPE_LEVEL_HIGH>,
					<0 0 0 2 &intc 141 IRQ_TYPE_LEVEL_HIGH>,
					<0 0 0 3 &intc 142 IRQ_TYPE_LEVEL_HIGH>,
					<0 0 0 4 &intc 143 IRQ_TYPE_LEVEL_HIGH>;
			interrupt-map-mask = <0 0 0 7>;
			interrupt-parent = <&intc>;
			interrupts = <139 IRQ_TYPE_LEVEL_HIGH>;
			interrupt-names = "msi";
			max-link-speed = <3>;
			num-lanes = <4>;
			phys = <&e16phy>;
			phy-names = "pcie";
			power-domains = <&scmi_power A210_PD_PCIE0>;
			resets = <&scmi_reset A210_RESET_PCIE_DM_GEN3X4_APBS_PRST>,
				 <&scmi_reset A210_RESET_PCIE_DM_GEN3X4_POWER_UP_RST>;
			reset-names = "dbi", "pwr";
			#size-cells = <2>;

			status = "disabled";
		};

		pcie1: pcie@b800000 {
			device_type = "pci";
			compatible = "zhihe,a210-pcie";
			reg = <0 0x0b800000 0 0x800000>,
			      <0x1e 0 0 0x20000>, <0 0x0a005000 0 0x1000>;
			reg-names = "dbi", "config", "app";
			ranges = <0x01000000 0 0 0x1e 0x200000 0 0x10000>,
				 <0x02000000 0 0x50100000 0 0x50100000 0 0x800000>,
				 <0x43000000 0x1e 0x300000 0x1e 0x300000
				 0 0x800000>;
			#address-cells = <3>;
			bus-range = <0 255>;
			clocks = <&scmi_clk A210_CLK_PCIE_RP_GEN3X1_AUX_CLK_EN>,
				 <&scmi_clk A210_CLK_PCIE_RP_GEN3X1_SLV_ACLK_EN>,
				 <&scmi_clk A210_CLK_PCIE_RP_GEN3X1_MST_ACLK_EN>,
				 <&scmi_clk A210_CLK_PCIE_RP_GEN3X1_PCLK_EN>;
			clock-names = "aux", "slv", "mstr", "dbi";
			#interrupt-cells = <1>;
			interrupt-map = <0 0 0 1 &intc 159 IRQ_TYPE_LEVEL_HIGH>,
					<0 0 0 2 &intc 160 IRQ_TYPE_LEVEL_HIGH>,
					<0 0 0 3 &intc 161 IRQ_TYPE_LEVEL_HIGH>,
					<0 0 0 4 &intc 162 IRQ_TYPE_LEVEL_HIGH>;
			interrupt-map-mask = <0 0 0 7>;
			interrupt-parent = <&intc>;
			interrupts = <158 IRQ_TYPE_LEVEL_HIGH>;
			interrupt-names = "msi";
			max-link-speed = <3>;
			num-lanes = <1>;
			phys = <&e16phy>;
			phy-names = "pcie";
			power-domains = <&scmi_power A210_PD_PCIE1>;
			resets = <&scmi_reset A210_RESET_PCIE_RP_GEN3X1_APBS_PRST>,
				 <&scmi_reset A210_RESET_PCIE_RP_GEN3X1_POWER_UP_RST>;
			reset-names = "dbi", "pwr";
			#size-cells = <2>;

			status = "disabled";
		};

		intc: interrupt-controller@18000000 {
			compatible = "zhihe,a210-plic", "thead,c900-plic";
			reg = <0x0 0x18000000 0x0 0x04000000>;
			#address-cells = <0>;
			#interrupt-cells = <2>;
			interrupt-controller;
			interrupts-extended = <&cpu0_intc 11>, <&cpu0_intc 9>,
					      <&cpu1_intc 11>, <&cpu1_intc 9>,
					      <&cpu2_intc 11>, <&cpu2_intc 9>,
					      <&cpu3_intc 11>, <&cpu3_intc 9>,
					      <&cpu4_intc 11>, <&cpu4_intc 9>,
					      <&cpu5_intc 11>, <&cpu5_intc 9>,
					      <&cpu6_intc 11>, <&cpu6_intc 9>,
					      <&cpu7_intc 11>, <&cpu7_intc 9>;
			riscv,ndev = <351>;
		};

		clint0: clint@1c000000 {
			compatible = "zhihe,a210-clint", "thead,c900-clint";
			reg = <0x0 0x1c000000 0x0 0x0000d800>;
			interrupts-extended = <&cpu0_intc 3>, <&cpu0_intc 7>,
					      <&cpu1_intc 3>, <&cpu1_intc 7>,
					      <&cpu2_intc 3>, <&cpu2_intc 7>,
					      <&cpu3_intc 3>, <&cpu3_intc 7>,
					      <&cpu4_intc 3>, <&cpu4_intc 7>,
					      <&cpu5_intc 3>, <&cpu5_intc 7>,
					      <&cpu6_intc 3>, <&cpu6_intc 7>,
					      <&cpu7_intc 3>, <&cpu7_intc 7>;
		};

		dmac1: dma-controller@27540000 {
			compatible = "zhihe,a210-axi-dma", "snps,axi-dma-1.01a";
			reg = <0x00 0x27540000 0x0 0x4000>;
			clocks = <&scmi_clk A210_CLK_TEE_DMAC_CLKEN>,
				 <&scmi_clk A210_CLK_TEE_DMAC_CLKEN>;
			clock-names = "core-clk", "cfgr-clk";
			#dma-cells = <1>;
			dma-channels = <4>;
			interrupt-parent = <&intc>;
			interrupts = <259 IRQ_TYPE_LEVEL_HIGH>;
			resets = <&scmi_reset A210_RESET_TEE_DMAC_ARST>,
				 <&scmi_reset A210_RESET_TEE_DMAC_HRST>;
			snps,axi-max-burst-len = <16>;
			snps,block-size = <65536 65536 65536 65536>;
			snps,data-width = <4>;
			snps,dma-masters = <1>;
			snps,priority = <0 0 0 0>;

			status = "disabled";
		};

		aon_gpio0: gpio@30841000 {
			compatible = "snps,dw-apb-gpio";
			reg = <0x00 0x30841000 0x0 0x1000>;
			#address-cells = <1>;
			clocks = <&scmi_clk A210_CLK_AON_SYS>, <&osc_32k>;
			clock-names = "bus", "db";
			#size-cells = <0>;

			ao_gpio0: gpio-controller@0 {
				compatible = "snps,dw-apb-gpio-port";
				reg = <0>;
				#gpio-cells = <2>;
				gpio-controller;
				gpio-ranges = <&aon_padctrl 0 7 15>,
					      <&aon_padctrl 21 22 11>;
				#interrupt-cells = <2>;
				interrupt-controller;
				interrupt-parent = <&intc>;
				interrupts = <17 IRQ_TYPE_LEVEL_HIGH>;
				ngpios = <32>;
			};
		};

		aon_padctrl: pinctrl@30848000 {
			compatible = "zhihe,a210-aon-pinctrl";
			reg = <0x0 0x30848000 0x0 0x2000>;
			clocks = <&scmi_clk A210_CLK_AON_SYS>;
			clock-names = "pclk";

			status = "disabled";
		};

		aoi2c1: i2c@30891000 {
			compatible = "snps,designware-i2c";
			reg = <0x00 0x30891000 0x0 0x1000>;
			#address-cells = <1>;
			clocks = <&scmi_clk A210_CLK_AON_I2C1_IC>,
				 <&scmi_clk A210_CLK_AON_I2C1_PCLK>;
			clock-names = "ref", "pclk";
			resets = <&scmi_reset A210_RESET_AON_I2C1>;
			interrupt-parent = <&intc>;
			interrupts = <20 IRQ_TYPE_LEVEL_HIGH>;
			#size-cells = <0>;

			status = "disabled";
		};

		aon_gpio1: gpio@30897000 {
			compatible = "snps,dw-apb-gpio";
			reg = <0x00 0x30897000 0x0 0x1000>;
			#address-cells = <1>;
			clocks = <&scmi_clk A210_CLK_AON_SYS>, <&osc_32k>;
			clock-names = "bus", "db";
			#size-cells = <0>;

			ao_gpio1: gpio-controller@0 {
				compatible = "snps,dw-apb-gpio-port";
				reg = <0>;
				#gpio-cells = <2>;
				gpio-controller;
				gpio-ranges = <&aon_padctrl 0 33 10>;
				#interrupt-cells = <2>;
				interrupt-controller;
				interrupt-parent = <&intc>;
				interrupts = <10 IRQ_TYPE_LEVEL_HIGH>;
				ngpios = <10>;
			};
		};

		sram@30907c00 {
			compatible = "mmio-sram";
			reg = <0 0x30907c00 0 0x200>;
			#address-cells = <1>;
			#size-cells = <1>;
			ranges = <0 0 0x30907c00 0x200>;

			scmi_shmem: scp-sram@0 {
				compatible = "arm,scmi-shmem";
				reg = <0 0x100>;
			};

			scmi_notification_shmem: scp-sram@100 {
				compatible = "arm,scmi-shmem";
				reg = <0x100 0x100>;
			};
		};
	};

	stmmac_axi_setup: stmmac-axi-config {
		snps,blen = <16 8 4 0 0 0 0>;
		snps,rd_osr_lmt = <7>;
		snps,wr_osr_lmt = <7>;
	};
};
